# CY8C5868AXI_LP035 register map
File version: 0.1
Registers are 8-bit, read-write, no defined reset value unless marked. A register's access mark holds for its fields unless they carry their own. Offsets are from the block's base; [hi:lo] are bit positions; {n}, {i} and the like mark numbered series; 'fields as' and 'values as' point back to an identical list.

## PWM_isr
Base 0x00000000
0x4000642C PWM_isr_COMPARE_Reg 16-bit — UDB.D0 - Assigned Compare Value
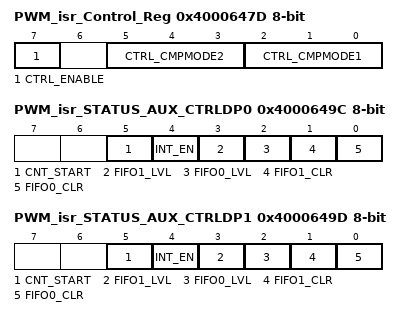
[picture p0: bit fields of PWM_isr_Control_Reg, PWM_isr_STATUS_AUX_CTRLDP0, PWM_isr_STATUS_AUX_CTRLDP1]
0x4000647D PWM_isr_Control_Reg — UDB Control Register - Assigned Control Register Value
  [7] CTRL_ENABLE — Enable the PWM
  [5:3] CTRL_CMPMODE2 — Compare mode 2
  [2:0] CTRL_CMPMODE1 — Compare mode 1
0x4000649C PWM_isr_STATUS_AUX_CTRLDP0 — UDB Auxilliary Control Register
  [5] CNT_START — FIFO0 clear
    0=E_CNT_START0 (Disable counter); 1=E_CNT_START1 (Enable counter)
  [4] INT_EN
    0=E_INT_EN0 (Interrupt disabled); 1=E_INT_EN1 (Interrupt enabled)
  [3] FIFO1_LVL — FIFO level
    0=E_FIFO_LVL_0 (FIFO LVL: input mode: FIFO not full; output mode: FIFO not empty); 1=E_FIFO_LVL_1 (FIFO LVL: input mode: FIFO at least 1/2 empty; output mode: FIFO at least 1/2 full)
  [2] FIFO0_LVL — FIFO level
    values as FIFO1_LVL
  [1] FIFO1_CLR — FIFO1 clear
    0=E_FIFO_CLR_0 (Normal FIFO operation); 1=E_FIFO_CLR_1 (Clear FIFO state)
  [0] FIFO0_CLR — FIFO0 clear
    values as FIFO1_CLR
0x4000649D PWM_isr_STATUS_AUX_CTRLDP1 — UDB Auxilliary Control Register
  fields as PWM_isr_STATUS_AUX_CTRLDP0

## USBFS
Base 0x00000000
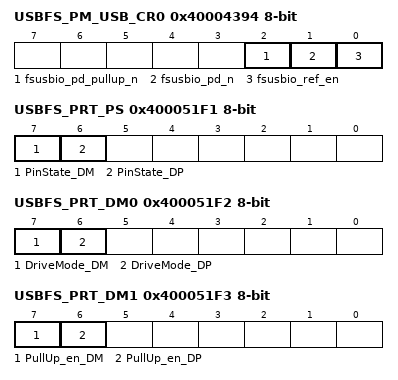
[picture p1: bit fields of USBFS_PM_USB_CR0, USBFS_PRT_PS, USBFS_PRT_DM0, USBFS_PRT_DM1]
0x40004394 USBFS_PM_USB_CR0 — USB Power Mode Control Register 0
  [2] fsusbio_pd_pullup_n, [1] fsusbio_pd_n, [0] fsusbio_ref_en
0x400043A5 USBFS_PM_ACT_CFG — Active Power Mode Configuration Register
0x400043B5 USBFS_PM_STBY_CFG — Standby Power Mode Configuration Register
0x400051F1 USBFS_PRT_PS — Port Pin State Register
  [7] PinState_DM ro, [6] PinState_DP ro
0x400051F2 USBFS_PRT_DM0 — Port Drive Mode Register
  [7] DriveMode_DM, [6] DriveMode_DP
0x400051F3 USBFS_PRT_DM1 — Port Drive Mode Register
  [7] PullUp_en_DM, [6] PullUp_en_DP
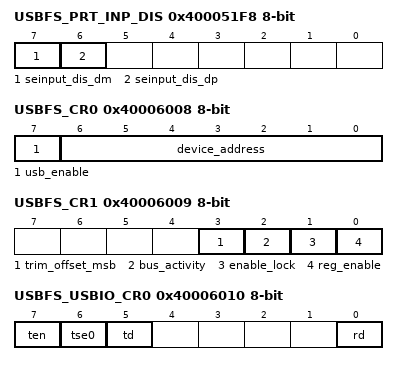
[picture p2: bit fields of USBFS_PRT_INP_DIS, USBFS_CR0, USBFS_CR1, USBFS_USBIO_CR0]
0x400051F8 USBFS_PRT_INP_DIS — Input buffer disable override
  [7] seinput_dis_dm, [6] seinput_dis_dp
0x40006000 USBFS_EP0_DR0 — bmRequestType
0x40006001 USBFS_EP0_DR1 — bRequest
0x40006002 USBFS_EP0_DR2 — wValueLo
0x40006003 USBFS_EP0_DR3 — wValueHi
0x40006004 USBFS_EP0_DR4 — wIndexLo
0x40006005 USBFS_EP0_DR5 — wIndexHi
0x40006006 USBFS_EP0_DR6 — lengthLo
0x40006007 USBFS_EP0_DR7 — lengthHi
0x40006008 USBFS_CR0 — USB Control Register 0
  [7] usb_enable, [6:0] device_address ro
0x40006009 USBFS_CR1 — USB Control Register 1
  [3] trim_offset_msb, [2] bus_activity, [1] enable_lock, [0] reg_enable
{0x40005FFE+0x10*i} USBFS_SIE_EP{i}_CR0 (i=1..8) — The Endpoint{i} Control Register
0x40006010 USBFS_USBIO_CR0 — USBIO Control Register 0
  [7] ten, [6] tse0, [5] td, [0] rd ro
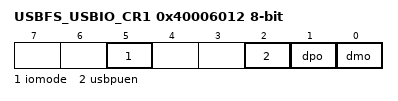
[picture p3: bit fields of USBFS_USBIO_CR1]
0x40006012 USBFS_USBIO_CR1 — USBIO Control Register 1
  [5] iomode, [2] usbpuen, [1] dpo ro, [0] dmo ro
0x4000608C USBFS_BUF_SIZE — Dedicated Endpoint Buffer Size Register
0x4000608E USBFS_EP_ACTIVE — Endpoint Active Indication Register
0x4000608F USBFS_EP_TYPE — Endpoint Type (IN/OUT) Indication
0x4000609D USBFS_USB_CLK_EN — USB Block Clock Enable Register

## IDAC_lsb
Base 0x00000000
0x400043A8 IDAC8_PM_ACT_CFG — Active Power Mode Configuration Register 8
  [3:0] en_dac — Enable DAC block(s). Populated subsystems are counted from the LSB.
0x400043B8 IDAC8_PM_STBY_CFG — Standby Power Mode Configuration Register 8
  fields as IDAC8_PM_ACT_CFG
0x4000460B IDAC8_TR
  [7:0] tr — 8 Calibration bits
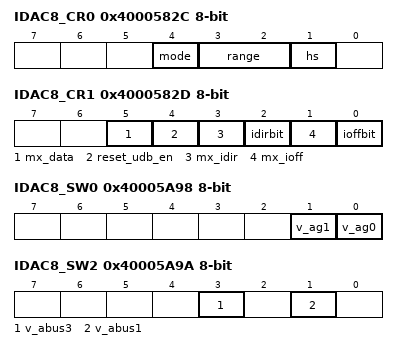
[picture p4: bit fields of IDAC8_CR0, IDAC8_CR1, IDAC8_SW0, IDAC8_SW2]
0x4000582C IDAC8_CR0 — DAC Block Control Register 0
  [4] mode ro — Mode Bit
    0=DAC_MODE_V (voltage DAC); 1=DAC_MODE_I (current DAC)
  [3:2] range — Ranges for mode=0 (VDAC) and mode=1 (IDAC)
    0=DAC_RANGE_0 (x0=0V to 4*vref (1.024V); 0 to 31.875uA); 1=DAC_RANGE_1 (x1=0V to 16*vref (4.096V); 0 to 255uA); 2=DAC_RANGE_2 (x0=0V to 4*vref (1.024V); 0 to 2.040mA); 3=DAC_RANGE_3 (x1=0V to 16*vref (4.096V); not used)
  [1] hs — High Speed Bit
    0=DAC_HS_LOWPOWER (regular (low power)); 1=DAC_HS_HIGHSPEED (high speed (higher power))
0x4000582D IDAC8_CR1 — DAC Block Control Register 1
  [5] mx_data — Select DATA source
    0=MX_DATA_REG (Select register source); 1=MX_DATA_UDB (Select UDB source)
  [4] reset_udb_en — DAC reset enable
    0=RESET_UDB_EN_DISABLE (Disable DAC Reset Source from UDB); 1=RESET_UDB_EN_ENABLE (Enable DAC Reset Source from UDB)
  [3] mx_idir — Mux selection for DAC current direction control
    0=MX_IDIR_REG (Register source idirbit selected); 1=MX_IDIR_UDB (UDB ictrl selected)
  [2] idirbit — register source for DAC current direction
  [1] mx_ioff — Mux selection for DAC current off control
    0=MX_IOFF_REG (Register source ioffbit selected); 1=MX_IOFF_UDB (UDB ictrl selected)
  [0] ioffbit — register source for DAC current off
0x40005A98 IDAC8_SW0 — DAC Analog Routing Register 0
  [1] v_ag1 — Connect voltage output to analog global of same side
    0=AG_NC (not connected); 1=AG_CONNECTED (Connect to Analog Global)
  [0] v_ag0 — Connect voltage output to analog global of same side
    values as v_ag1
0x40005A9A IDAC8_SW2 — DAC Analog Routing Register 2
  [3] v_abus3 — Connect voltage output to analog (local) bus of the same side
    0=ABUS_NC (not connected); 1=ABUS_CONNECTED (Connect to Analog (local) Bus)
  [1] v_abus1 — Connect voltage output to analog (local) bus of the same side
    values as v_abus3
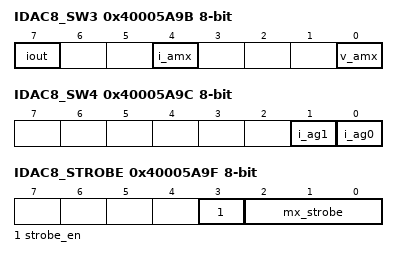
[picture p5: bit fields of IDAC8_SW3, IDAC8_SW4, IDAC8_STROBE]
0x40005A9B IDAC8_SW3 — DAC Analog Routing Register 3
  [7] iout — Connect current output to pad
    0=IOUT_NC (not connected); 1=IOUT_CONNECT (Connect to pad)
  [4] i_amx — Connect current output to Analog Mux Bus
    0=AMX_NC (not connected); 1=AMX_CONNECTED (Connect to AMUXBUS)
  [0] v_amx — Connect voltage output to Analog Mux Bus
    values as i_amx
0x40005A9C IDAC8_SW4 — DAC Analog Routing Register 4
  [1] i_ag1 — Connect current output to analog global of same side
    values as IDAC8_SW0.v_ag1
  [0] i_ag0 — Connect current output to analog global of same side
    values as IDAC8_SW0.v_ag1
0x40005A9F IDAC8_STROBE — DAC Strobe Register
  [3] strobe_en — Strobe gating control
    0=disable strobe; 1=enable strobe
  [2:0] mx_strobe — Strobe source selection
    0=MX_STROBE_BUSWRITE (Select bus write strobe source); 1=MX_STROBE_UDB_SRC (Select UDB strobe source); 2=MX_STROBE_NC_2 (NC); 3=MX_STROBE_NC_3 (NC); {v}=MX_STROBE_CLK_A{v-4}_DIG (Select clk_a{v-4}_dig) (v=4..7)
0x40005B83 IDAC8_D — DAC Data Register
  [7:0] data — 8 DAC Data bits

## IDAC_msb
Base 0x00000000
0x400043A8 IDAC8_PM_ACT_CFG — Active Power Mode Configuration Register 8
  [3:0] en_dac — Enable DAC block(s). Populated subsystems are counted from the LSB.
0x400043B8 IDAC8_PM_STBY_CFG — Standby Power Mode Configuration Register 8
  fields as IDAC8_PM_ACT_CFG
0x40004609 IDAC8_TR
  [7:0] tr — 8 Calibration bits
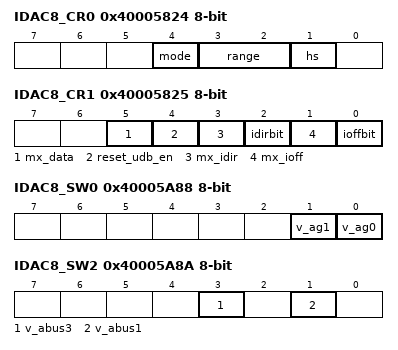
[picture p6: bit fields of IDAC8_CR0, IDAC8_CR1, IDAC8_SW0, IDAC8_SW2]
0x40005824 IDAC8_CR0 — DAC Block Control Register 0
  [4] mode ro — Mode Bit
    0=DAC_MODE_V (voltage DAC); 1=DAC_MODE_I (current DAC)
  [3:2] range — Ranges for mode=0 (VDAC) and mode=1 (IDAC)
    0=DAC_RANGE_0 (x0=0V to 4*vref (1.024V); 0 to 31.875uA); 1=DAC_RANGE_1 (x1=0V to 16*vref (4.096V); 0 to 255uA); 2=DAC_RANGE_2 (x0=0V to 4*vref (1.024V); 0 to 2.040mA); 3=DAC_RANGE_3 (x1=0V to 16*vref (4.096V); not used)
  [1] hs — High Speed Bit
    0=DAC_HS_LOWPOWER (regular (low power)); 1=DAC_HS_HIGHSPEED (high speed (higher power))
0x40005825 IDAC8_CR1 — DAC Block Control Register 1
  [5] mx_data — Select DATA source
    0=MX_DATA_REG (Select register source); 1=MX_DATA_UDB (Select UDB source)
  [4] reset_udb_en — DAC reset enable
    0=RESET_UDB_EN_DISABLE (Disable DAC Reset Source from UDB); 1=RESET_UDB_EN_ENABLE (Enable DAC Reset Source from UDB)
  [3] mx_idir — Mux selection for DAC current direction control
    0=MX_IDIR_REG (Register source idirbit selected); 1=MX_IDIR_UDB (UDB ictrl selected)
  [2] idirbit — register source for DAC current direction
  [1] mx_ioff — Mux selection for DAC current off control
    0=MX_IOFF_REG (Register source ioffbit selected); 1=MX_IOFF_UDB (UDB ictrl selected)
  [0] ioffbit — register source for DAC current off
0x40005A88 IDAC8_SW0 — DAC Analog Routing Register 0
  [1] v_ag1 — Connect voltage output to analog global of same side
    0=AG_NC (not connected); 1=AG_CONNECTED (Connect to Analog Global)
  [0] v_ag0 — Connect voltage output to analog global of same side
    values as v_ag1
0x40005A8A IDAC8_SW2 — DAC Analog Routing Register 2
  [3] v_abus3 — Connect voltage output to analog (local) bus of the same side
    0=ABUS_NC (not connected); 1=ABUS_CONNECTED (Connect to Analog (local) Bus)
  [1] v_abus1 — Connect voltage output to analog (local) bus of the same side
    values as v_abus3
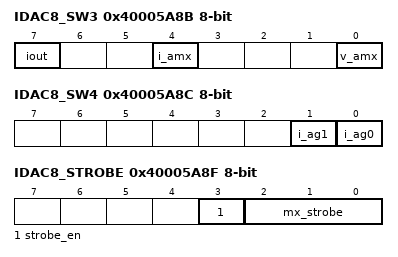
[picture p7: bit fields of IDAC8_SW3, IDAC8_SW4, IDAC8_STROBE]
0x40005A8B IDAC8_SW3 — DAC Analog Routing Register 3
  [7] iout — Connect current output to pad
    0=IOUT_NC (not connected); 1=IOUT_CONNECT (Connect to pad)
  [4] i_amx — Connect current output to Analog Mux Bus
    0=AMX_NC (not connected); 1=AMX_CONNECTED (Connect to AMUXBUS)
  [0] v_amx — Connect voltage output to Analog Mux Bus
    values as i_amx
0x40005A8C IDAC8_SW4 — DAC Analog Routing Register 4
  [1] i_ag1 — Connect current output to analog global of same side
    values as IDAC8_SW0.v_ag1
  [0] i_ag0 — Connect current output to analog global of same side
    values as IDAC8_SW0.v_ag1
0x40005A8F IDAC8_STROBE — DAC Strobe Register
  [3] strobe_en — Strobe gating control
    0=disable strobe; 1=enable strobe
  [2:0] mx_strobe — Strobe source selection
    0=MX_STROBE_BUSWRITE (Select bus write strobe source); 1=MX_STROBE_UDB_SRC (Select UDB strobe source); 2=MX_STROBE_NC_2 (NC); 3=MX_STROBE_NC_3 (NC); {v}=MX_STROBE_CLK_A{v-4}_DIG (Select clk_a{v-4}_dig) (v=4..7)
0x40005B81 IDAC8_D — DAC Data Register
  [7:0] data — 8 DAC Data bits
